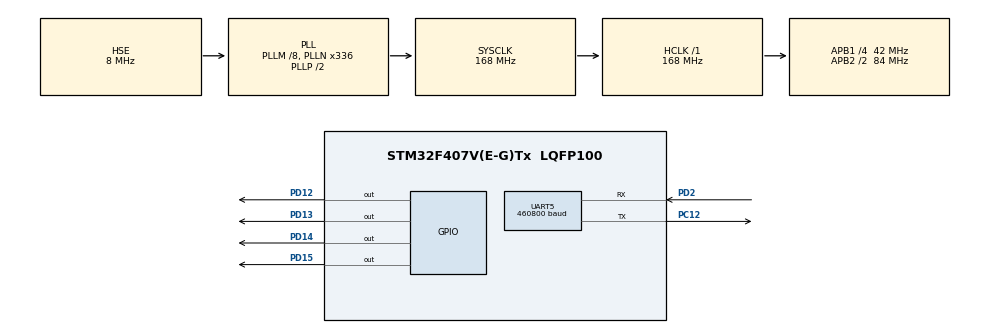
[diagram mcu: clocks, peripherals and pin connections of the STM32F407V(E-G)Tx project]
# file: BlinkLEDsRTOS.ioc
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Dma.Request0=UART5_RX
Dma.Request1=UART5_TX
Dma.UART5_RX.0.Direction=DMA_PERIPH_TO_MEMORY
Dma.UART5_RX.0.FIFOMode=DMA_FIFOMODE_DISABLE
Dma.UART5_RX.0.Instance=DMA1_Stream0
Dma.UART5_RX.0.MemDataAlignment=DMA_MDATAALIGN_BYTE
Dma.UART5_RX.0.MemInc=DMA_MINC_ENABLE
Dma.UART5_RX.0.Mode=DMA_NORMAL
Dma.UART5_RX.0.PeriphDataAlignment=DMA_PDATAALIGN_BYTE
Dma.UART5_RX.0.PeriphInc=DMA_PINC_DISABLE
Dma.UART5_RX.0.Priority=DMA_PRIORITY_LOW
Dma.UART5_TX.1.Direction=DMA_MEMORY_TO_PERIPH
Dma.UART5_TX.1.FIFOMode=DMA_FIFOMODE_DISABLE
Dma.UART5_TX.1.Instance=DMA1_Stream7
Dma.UART5_TX.1.MemDataAlignment=DMA_MDATAALIGN_BYTE
Dma.UART5_TX.1.MemInc=DMA_MINC_ENABLE
Dma.UART5_TX.1.Mode=DMA_CIRCULAR
Dma.UART5_TX.1.PeriphDataAlignment=DMA_PDATAALIGN_BYTE
Dma.UART5_TX.1.PeriphInc=DMA_PINC_DISABLE
Dma.UART5_TX.1.Priority=DMA_PRIORITY_LOW
FREERTOS.Tasks01=defaultTask,-3,128,StartDefaultTask,Default,NULL,Dynamic,NULL,NULL;blinkLED1Task,0,128,StartTask02,Default,NULL,Dynamic,NULL,NULL
FREERTOS.configUSE_TIMERS=1
Mcu.Family=STM32F4
Mcu.Name=STM32F407V(E-G)Tx
Mcu.Package=LQFP100
NVIC.DMA1_Stream0_IRQn=true\:5\:0\:false\:false\:true\:true\:false
NVIC.DMA1_Stream7_IRQn=true\:5\:0\:false\:false\:true\:true\:false
NVIC.PriorityGroup=NVIC_PRIORITYGROUP_4
NVIC.TIM1_UP_TIM10_IRQn=true\:5\:0\:false\:false\:true\:true\:false
NVIC.TimeBase=TIM1_UP_TIM10_IRQn
NVIC.TimeBaseIP=TIM1
PC12.Mode=Asynchronous
PC12.Signal=UART5_TX
PD12.Signal=GPIO_Output
PD13.Signal=GPIO_Output
PD14.Signal=GPIO_Output
PD15.Signal=GPIO_Output
PD2.Mode=Asynchronous
PD2.Signal=UART5_RX
PH0-OSC_IN.Mode=HSE-External-Oscillator
PH0-OSC_IN.Signal=RCC_OSC_IN
PH1-OSC_OUT.Mode=HSE-External-Oscillator
PH1-OSC_OUT.Signal=RCC_OSC_OUT
ProjectManager.HeapSize=0x200
ProjectManager.StackSize=0x400
ProjectManager.TargetToolchain=SW4STM32
RCC.48MHZClocksFreq_Value=84000000
RCC.AHBFreq_Value=168000000
RCC.APB1CLKDivider=RCC_HCLK_DIV4
RCC.APB1Freq_Value=42000000
RCC.APB1TimFreq_Value=84000000
RCC.APB2CLKDivider=RCC_HCLK_DIV2
RCC.APB2Freq_Value=84000000
RCC.APB2TimFreq_Value=168000000
RCC.CortexFreq_Value=168000000
RCC.HCLKFreq_Value=168000000
RCC.HSE_VALUE=8000000
RCC.HSI_VALUE=16000000
RCC.LSE_VALUE=32768
RCC.PLLM=8
RCC.PLLN=336
RCC.PLLSourceVirtual=RCC_PLLSOURCE_HSE
RCC.SYSCLKFreq_VALUE=168000000
RCC.SYSCLKSource=RCC_SYSCLKSOURCE_PLLCLK
RCC.VCOOutputFreq_Value=336000000
UART5.BaudRate=460800
UART5.VirtualMode=Asynchronous
VP_FREERTOS_VS_ENABLE.Mode=Enabled
VP_SYS_VS_tim1.Mode=TIM1
board=BlinkLEDsRTOS

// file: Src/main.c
/**
  ******************************************************************************
  * File Name          : main.c
  * Description        : Main program body
  ******************************************************************************
  * This notice applies to any and all portions of this file
  * that are not between comment pairs USER CODE BEGIN and
  * USER CODE END. Other portions of this file, whether
  * inserted by the user or by software development tools
  * are owned by their respective copyright owners.
  *
  * Copyright (c) 2018 STMicroelectronics International N.V.
  * All rights reserved.
  *
  * Redistribution and use in source and binary forms, with or without
  * modification, are permitted, provided that the following conditions are met:
  *
  * 1. Redistribution of source code must retain the above copyright notice,
  *    this list of conditions and the following disclaimer.
  * 2. Redistributions in binary form must reproduce the above copyright notice,
  *    this list of conditions and the following disclaimer in the documentation
  *    and/or other materials provided with the distribution.
  * 3. Neither the name of STMicroelectronics nor the names of other
  *    contributors to this software may be used to endorse or promote products
  *    derived from this software without specific written permission.
  * 4. This software, including modifications and/or derivative works of this
  *    software, must execute solely and exclusively on microcontroller or
  *    microprocessor devices manufactured by or for STMicroelectronics.
  * 5. Redistribution and use of this software other than as permitted under
  *    this license is void and will automatically terminate your rights under
  *    this license.
  *
  * THIS SOFTWARE IS PROVIDED BY STMICROELECTRONICS AND CONTRIBUTORS "AS IS"
  * AND ANY EXPRESS, IMPLIED OR STATUTORY WARRANTIES, INCLUDING, BUT NOT
  * LIMITED TO, THE IMPLIED WARRANTIES OF MERCHANTABILITY, FITNESS FOR A
  * PARTICULAR PURPOSE AND NON-INFRINGEMENT OF THIRD PARTY INTELLECTUAL PROPERTY
  * RIGHTS ARE DISCLAIMED TO THE FULLEST EXTENT PERMITTED BY LAW. IN NO EVENT
  * SHALL STMICROELECTRONICS OR CONTRIBUTORS BE LIABLE FOR ANY DIRECT, INDIRECT,
  * INCIDENTAL, SPECIAL, EXEMPLARY, OR CONSEQUENTIAL DAMAGES (INCLUDING, BUT NOT
  * LIMITED TO, PROCUREMENT OF SUBSTITUTE GOODS OR SERVICES; LOSS OF USE, DATA,
  * OR PROFITS; OR BUSINESS INTERRUPTION) HOWEVER CAUSED AND ON ANY THEORY OF
  * LIABILITY, WHETHER IN CONTRACT, STRICT LIABILITY, OR TORT (INCLUDING
  * NEGLIGENCE OR OTHERWISE) ARISING IN ANY WAY OUT OF THE USE OF THIS SOFTWARE,
  * EVEN IF ADVISED OF THE POSSIBILITY OF SUCH DAMAGE.
  *
  ******************************************************************************
  */

#include "main.h"
#include "stm32f4xx_hal.h"
#include "cmsis_os.h"

UART_HandleTypeDef huart5;
DMA_HandleTypeDef hdma_uart5_rx;
DMA_HandleTypeDef hdma_uart5_tx;

osThreadId defaultTaskHandle;
osThreadId blinkLED1TaskHandle;

/* USER CODE BEGIN PV */
/* Private variables ---------------------------------------------------------*/

/* USER CODE END PV */

void SystemClock_Config(void);
static void MX_GPIO_Init(void);
static void MX_DMA_Init(void);
static void MX_UART5_Init(void);
void StartDefaultTask(void const * argument);
void StartTask02(void const * argument);

/* USER CODE BEGIN PFP */
/* Private function prototypes -----------------------------------------------*/

/* USER CODE END PFP */

int main(void)
{

  /* MCU Configuration----------------------------------------------------------*/

  /* Reset of all peripherals, Initializes the Flash interface and the Systick. */
  HAL_Init();

  /* Configure the system clock */
  SystemClock_Config();

  /* Initialize all configured peripherals */
  MX_GPIO_Init();
  MX_DMA_Init();
  MX_UART5_Init();

  /* Create the thread(s) */
  /* definition and creation of defaultTask */
  osThreadDef(defaultTask, StartDefaultTask, osPriorityIdle, 0, 128);
  defaultTaskHandle = osThreadCreate(osThread(defaultTask), NULL);

  /* definition and creation of blinkLED1Task */
  osThreadDef(blinkLED1Task, StartTask02, osPriorityNormal, 0, 128);
  blinkLED1TaskHandle = osThreadCreate(osThread(blinkLED1Task), NULL);

  /* Start scheduler */
  osKernelStart();

  /* We should never get here as control is now taken by the scheduler */

  /* Infinite loop */
  while (1)
  {

  }

}

/** System Clock Configuration
*/
void SystemClock_Config(void)
{

  RCC_OscInitTypeDef RCC_OscInitStruct;
  RCC_ClkInitTypeDef RCC_ClkInitStruct;

    /**Configure the main internal regulator output voltage
    */
  __HAL_RCC_PWR_CLK_ENABLE();

  __HAL_PWR_VOLTAGESCALING_CONFIG(PWR_REGULATOR_VOLTAGE_SCALE1);

    /**Initializes the CPU, AHB and APB busses clocks
    */
  RCC_OscInitStruct.OscillatorType = RCC_OSCILLATORTYPE_HSE;
  RCC_OscInitStruct.HSEState = RCC_HSE_ON;
  RCC_OscInitStruct.PLL.PLLState = RCC_PLL_ON;
  RCC_OscInitStruct.PLL.PLLSource = RCC_PLLSOURCE_HSE;
  RCC_OscInitStruct.PLL.PLLM = 8;
  RCC_OscInitStruct.PLL.PLLN = 336;
  RCC_OscInitStruct.PLL.PLLP = RCC_PLLP_DIV2;
  RCC_OscInitStruct.PLL.PLLQ = 4;
  if (HAL_RCC_OscConfig(&RCC_OscInitStruct) != HAL_OK)
  {
    _Error_Handler(__FILE__, __LINE__);
  }

    /**Initializes the CPU, AHB and APB busses clocks
    */
  RCC_ClkInitStruct.ClockType = RCC_CLOCKTYPE_HCLK|RCC_CLOCKTYPE_SYSCLK
                              |RCC_CLOCKTYPE_PCLK1|RCC_CLOCKTYPE_PCLK2;
  RCC_ClkInitStruct.SYSCLKSource = RCC_SYSCLKSOURCE_PLLCLK;
  RCC_ClkInitStruct.AHBCLKDivider = RCC_SYSCLK_DIV1;
  RCC_ClkInitStruct.APB1CLKDivider = RCC_HCLK_DIV4;
  RCC_ClkInitStruct.APB2CLKDivider = RCC_HCLK_DIV2;

  if (HAL_RCC_ClockConfig(&RCC_ClkInitStruct, FLASH_LATENCY_5) != HAL_OK)
  {
    _Error_Handler(__FILE__, __LINE__);
  }

    /**Configure the Systick interrupt time
    */
  HAL_SYSTICK_Config(HAL_RCC_GetHCLKFreq()/1000);

    /**Configure the Systick
    */
  HAL_SYSTICK_CLKSourceConfig(SYSTICK_CLKSOURCE_HCLK);

  /* SysTick_IRQn interrupt configuration */
  HAL_NVIC_SetPriority(SysTick_IRQn, 15, 0);
}

/* UART5 init function */
static void MX_UART5_Init(void)
{

  huart5.Instance = UART5;
  huart5.Init.BaudRate = 460800;
  huart5.Init.WordLength = UART_WORDLENGTH_8B;
  huart5.Init.StopBits = UART_STOPBITS_1;
  huart5.Init.Parity = UART_PARITY_NONE;
  huart5.Init.Mode = UART_MODE_TX_RX;
  huart5.Init.HwFlowCtl = UART_HWCONTROL_NONE;
  huart5.Init.OverSampling = UART_OVERSAMPLING_16;
  if (HAL_UART_Init(&huart5) != HAL_OK)
  {
    _Error_Handler(__FILE__, __LINE__);
  }

}

static void MX_DMA_Init(void)
{
  /* DMA controller clock enable */
  __HAL_RCC_DMA1_CLK_ENABLE();

  /* DMA interrupt init */
  /* DMA1_Stream0_IRQn interrupt configuration */
  HAL_NVIC_SetPriority(DMA1_Stream0_IRQn, 5, 0);
  HAL_NVIC_EnableIRQ(DMA1_Stream0_IRQn);
  /* DMA1_Stream7_IRQn interrupt configuration */
  HAL_NVIC_SetPriority(DMA1_Stream7_IRQn, 5, 0);
  HAL_NVIC_EnableIRQ(DMA1_Stream7_IRQn);

}

/** Configure pins as
        * Analog
        * Input
        * Output
        * EVENT_OUT
        * EXTI
*/
static void MX_GPIO_Init(void)
{

  GPIO_InitTypeDef GPIO_InitStruct;

  /* GPIO Ports Clock Enable */
  __HAL_RCC_GPIOH_CLK_ENABLE();
  __HAL_RCC_GPIOD_CLK_ENABLE();
  __HAL_RCC_GPIOC_CLK_ENABLE();

  /*Configure GPIO pin Output Level */
  HAL_GPIO_WritePin(GPIOD, GPIO_PIN_12|GPIO_PIN_13|GPIO_PIN_14|GPIO_PIN_15, GPIO_PIN_RESET);

  /*Configure GPIO pins : PD12 PD13 PD14 PD15 */
  GPIO_InitStruct.Pin = GPIO_PIN_12|GPIO_PIN_13|GPIO_PIN_14|GPIO_PIN_15;
  GPIO_InitStruct.Mode = GPIO_MODE_OUTPUT_PP;
  GPIO_InitStruct.Pull = GPIO_NOPULL;
  GPIO_InitStruct.Speed = GPIO_SPEED_FREQ_LOW;
  HAL_GPIO_Init(GPIOD, &GPIO_InitStruct);

}

/* StartDefaultTask function */
void StartDefaultTask(void const * argument)
{

  for(;;)
  {
    osDelay(1);
  }
}

/* StartTask02 function */
void StartTask02(void const * argument)
{
  /* USER CODE BEGIN StartTask02 */
  /* Infinite loop */
  for(;;)
  {
	HAL_GPIO_TogglePin(GPIOD,GPIO_PIN_12);
    osDelay(200);
  }
  /* USER CODE END StartTask02 */
}

void HAL_TIM_PeriodElapsedCallback(TIM_HandleTypeDef *htim)
{
  if (htim->Instance == TIM1) {
    HAL_IncTick();
  }
}

void _Error_Handler(char * file, int line)
{
  while(1)
  {
  }
}

/************************ (C) COPYRIGHT STMicroelectronics *****END OF FILE****/
